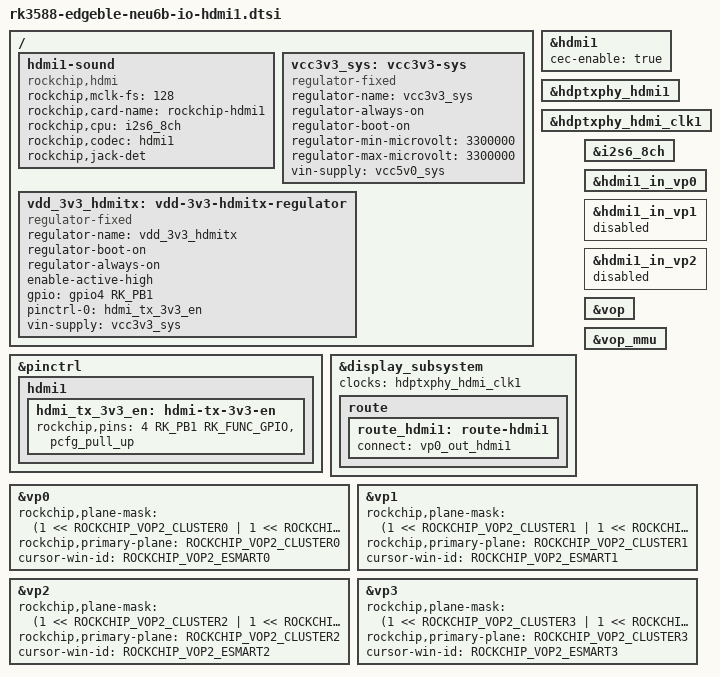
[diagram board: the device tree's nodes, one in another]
// SPDX-License-Identifier: (GPL-2.0+ OR MIT)
/*
 * Copyright (c) 2023 Edgeble AI Technologies Pvt. Ltd.
 */

/* HDMI1 */
/ {
	hdmi1-sound {
		status = "okay";
		compatible = "rockchip,hdmi";
		rockchip,mclk-fs = <128>;
		rockchip,card-name = "rockchip-hdmi1";
		rockchip,cpu = <&i2s6_8ch>;
		rockchip,codec = <&hdmi1>;
		rockchip,jack-det;
	};

	vcc3v3_sys: vcc3v3-sys {
		compatible = "regulator-fixed";
		regulator-name = "vcc3v3_sys";
		regulator-always-on;
		regulator-boot-on;
		regulator-min-microvolt = <3300000>;
		regulator-max-microvolt = <3300000>;
		vin-supply = <&vcc5v0_sys>;
	};

	vdd_3v3_hdmitx: vdd-3v3-hdmitx-regulator {
		compatible = "regulator-fixed";
		regulator-name = "vdd_3v3_hdmitx";
		regulator-boot-on;
		regulator-always-on;
		enable-active-high;
		gpio = <&gpio4 RK_PB1 GPIO_ACTIVE_HIGH>;
		pinctrl-names = "default";
		pinctrl-0 = <&hdmi_tx_3v3_en>;
		vin-supply = <&vcc3v3_sys>;
	};
};

&pinctrl {
	hdmi1 {
		hdmi_tx_3v3_en: hdmi-tx-3v3-en {
			rockchip,pins = <4 RK_PB1 RK_FUNC_GPIO &pcfg_pull_up>;
		};
	};
};

&hdmi1 {
	status = "okay";
        cec-enable = "true";
};

&hdptxphy_hdmi1 {
	status = "okay";
};

&hdptxphy_hdmi_clk1 {
	status = "okay";
};

&display_subsystem {
	clocks = <&hdptxphy_hdmi_clk1>;
	clock-names = "hdmi1_phy_pll";
};

&i2s6_8ch {
	status = "okay";
};

&display_subsystem {
	route {
		route_hdmi1: route-hdmi1 {
			status = "okay";
			connect = <&vp0_out_hdmi1>;
		};
	};
};

&hdmi1_in_vp0 {
	status = "okay";
};

&hdmi1_in_vp1 {
	status = "disabled";
};

&hdmi1_in_vp2 {
	status = "disabled";
};

&vop {
	status = "okay";
};

&vop_mmu {
	status = "okay";
};

/* vp0 & vp1 splice for 8K output */
&vp0 {
	rockchip,plane-mask = <(1 << ROCKCHIP_VOP2_CLUSTER0 | 1 << ROCKCHIP_VOP2_ESMART0)>;
	rockchip,primary-plane = <ROCKCHIP_VOP2_CLUSTER0>;
	cursor-win-id = <ROCKCHIP_VOP2_ESMART0>;
};

&vp1 {
	rockchip,plane-mask = <(1 << ROCKCHIP_VOP2_CLUSTER1 | 1 << ROCKCHIP_VOP2_ESMART1)>;
	rockchip,primary-plane = <ROCKCHIP_VOP2_CLUSTER1>;
	cursor-win-id = <ROCKCHIP_VOP2_ESMART1>;
};

&vp2 {
	rockchip,plane-mask = <(1 << ROCKCHIP_VOP2_CLUSTER2 | 1 << ROCKCHIP_VOP2_ESMART2)>;
	rockchip,primary-plane = <ROCKCHIP_VOP2_CLUSTER2>;
	cursor-win-id = <ROCKCHIP_VOP2_ESMART2>;
};

&vp3 {
	rockchip,plane-mask = <(1 << ROCKCHIP_VOP2_CLUSTER3 | 1 << ROCKCHIP_VOP2_ESMART3)>;
	rockchip,primary-plane = <ROCKCHIP_VOP2_CLUSTER3>;
	cursor-win-id = <ROCKCHIP_VOP2_ESMART3>;
};
